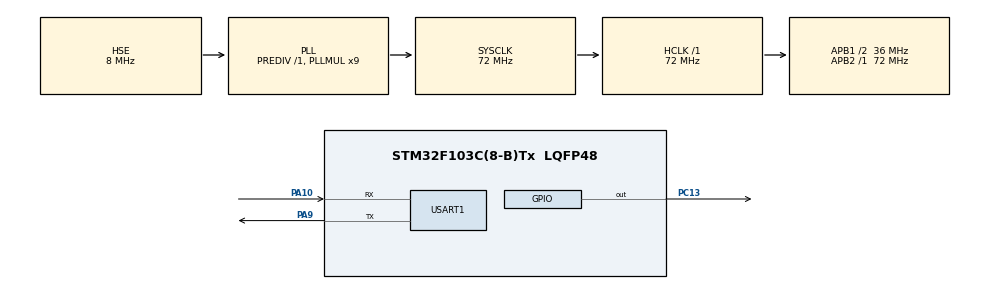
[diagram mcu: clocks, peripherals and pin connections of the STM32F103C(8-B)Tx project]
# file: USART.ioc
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Mcu.Family=STM32F1
Mcu.Name=STM32F103C(8-B)Tx
Mcu.Package=LQFP48
NVIC.PriorityGroup=NVIC_PRIORITYGROUP_4
NVIC.USART1_IRQn=true\:0\:0\:false\:false\:true\:true\:true\:true
PA10.Mode=Asynchronous
PA10.Signal=USART1_RX
PA13.Mode=Serial_Wire
PA13.Signal=SYS_JTMS-SWDIO
PA14.Mode=Serial_Wire
PA14.Signal=SYS_JTCK-SWCLK
PA9.Mode=Asynchronous
PA9.Signal=USART1_TX
PC13-TAMPER-RTC.Signal=GPIO_Output
PD0-OSC_IN.Mode=HSE-External-Oscillator
PD0-OSC_IN.Signal=RCC_OSC_IN
PD1-OSC_OUT.Mode=HSE-External-Oscillator
PD1-OSC_OUT.Signal=RCC_OSC_OUT
ProjectManager.HeapSize=0x200
ProjectManager.StackSize=0x400
ProjectManager.TargetToolchain=MDK-ARM V5.32
RCC.AHBFreq_Value=72000000
RCC.APB1CLKDivider=RCC_HCLK_DIV2
RCC.APB1Freq_Value=36000000
RCC.APB1TimFreq_Value=72000000
RCC.APB2Freq_Value=72000000
RCC.APB2TimFreq_Value=72000000
RCC.HCLKFreq_Value=72000000
RCC.PLLMUL=RCC_PLL_MUL9
RCC.PLLSourceVirtual=RCC_PLLSOURCE_HSE
RCC.SYSCLKFreq_VALUE=72000000
RCC.SYSCLKSource=RCC_SYSCLKSOURCE_PLLCLK
RCC.USBFreq_Value=72000000
USART1.VirtualMode=VM_ASYNC
board=custom

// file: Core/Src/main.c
/* USER CODE BEGIN Header */
/**
  ******************************************************************************
  * @file           : main.c
  * @brief          : Main program body
  ******************************************************************************
  * @attention
  *
  * Copyright (c) 2026 STMicroelectronics.
  * All rights reserved.
  *
  * This software is licensed under terms that can be found in the LICENSE file
  * in the root directory of this software component.
  * If no LICENSE file comes with this software, it is provided AS-IS.
  *
  ******************************************************************************
  */
/* USER CODE END Header */
#include "main.h"

UART_HandleTypeDef huart1;

/* rx_buffer and i are declared once, globally, further down (USER CODE BEGIN 4)
 * so that both main() and HAL_UART_RxCpltCallback() share the SAME variables
 * instead of main() writing to a local shadow copy. Declared volatile since
 * they are shared between interrupt context (the callback) and main(). */
/* USER CODE END PV */
void SystemClock_Config(void);
static void MX_GPIO_Init(void);
static void MX_USART1_UART_Init(void);

int main(void)
{

  /* MCU Configuration--------------------------------------------------------*/

  /* Reset of all peripherals, Initializes the Flash interface and the Systick. */
  HAL_Init();

  /* Configure the system clock */
  SystemClock_Config();

  /* Initialize all configured peripherals */
  MX_GPIO_Init();
  MX_USART1_UART_Init();
  /* USER CODE BEGIN 2 */
uint8_t DATA[] = "TEST \r \n";
uint8_t rx_buffer[12] = {0};
uint8_t i =0;
uint8_t data2[]={1,2,3,4};
  /* USER CODE END 2 */

  /* Infinite loop */
  /* USER CODE BEGIN WHILE */
  while (1)
  {

// TANSSMIT DATA WITH serial communication

		// Block until up to 12 bytes are received, or 5s timeout elapses.
		// rx_buffer will hold whatever bytes arrived (fewer than 12 if the
		// sender stops early, e.g. after pressing Enter in a terminal).
		HAL_UART_Receive (&huart1,rx_buffer, 12,5000);

		// Scan rx_buffer for a carriage return (ASCII 13, '\r'), which marks
		// the end of the line the user typed. i ends up pointing at the
		// index of that '\r'.
		// NOTE: if no '\r' is ever received (e.g. timeout with garbage or
		// no data), this loop reads past the buffer with no bound check —
		// fine for this quick training test, but not safe for production code.
		while(rx_buffer[i] != 13)i++;

		// Echo back only the bytes received before the '\r' (i.e. the
		// actual line content, not the '\r' itself or trailing buffer junk).
    HAL_UART_Transmit(&huart1,rx_buffer, i, 100);
		HAL_Delay(500);

/////////////////////// INCREMENTING COUNTER TEST (interrupt transmit) //////
		// Send only the first byte of data2 using interrupt-driven transmit.
		// HAL_UART_Transmit_IT() returns immediately; the actual transfer
		// happens in the background via USART1 interrupt.
    HAL_UART_Transmit_IT(&huart1,data2,1);

		// Give the interrupt transmit time to finish, and make each byte
		// visible on the receiving terminal at a readable pace.
		HAL_Delay(500);

		// Overwrite data2[0] with the current value of counter i, then
		// increment i for next time. Each loop iteration transmits the next
		// value in the sequence: 0, 1, 2, 3... This tests that repeated
		// interrupt-driven transmits work correctly back-to-back.
		data2[0]=i++;
///////////////////////////////////////////
    /* USER CODE END WHILE */

  }
}

void SystemClock_Config(void)
{
  RCC_OscInitTypeDef RCC_OscInitStruct = {0};
  RCC_ClkInitTypeDef RCC_ClkInitStruct = {0};

  /** Initializes the RCC Oscillators according to the specified parameters
  * in the RCC_OscInitTypeDef structure.
  */
  RCC_OscInitStruct.OscillatorType = RCC_OSCILLATORTYPE_HSE;
  RCC_OscInitStruct.HSEState = RCC_HSE_ON;
  RCC_OscInitStruct.HSEPredivValue = RCC_HSE_PREDIV_DIV1;
  RCC_OscInitStruct.HSIState = RCC_HSI_ON;
  RCC_OscInitStruct.PLL.PLLState = RCC_PLL_ON;
  RCC_OscInitStruct.PLL.PLLSource = RCC_PLLSOURCE_HSE;
  RCC_OscInitStruct.PLL.PLLMUL = RCC_PLL_MUL9;
  if (HAL_RCC_OscConfig(&RCC_OscInitStruct) != HAL_OK)
  {
    Error_Handler();
  }

  /** Initializes the CPU, AHB and APB buses clocks
  */
  RCC_ClkInitStruct.ClockType = RCC_CLOCKTYPE_HCLK|RCC_CLOCKTYPE_SYSCLK
                              |RCC_CLOCKTYPE_PCLK1|RCC_CLOCKTYPE_PCLK2;
  RCC_ClkInitStruct.SYSCLKSource = RCC_SYSCLKSOURCE_PLLCLK;
  RCC_ClkInitStruct.AHBCLKDivider = RCC_SYSCLK_DIV1;
  RCC_ClkInitStruct.APB1CLKDivider = RCC_HCLK_DIV2;
  RCC_ClkInitStruct.APB2CLKDivider = RCC_HCLK_DIV1;

  if (HAL_RCC_ClockConfig(&RCC_ClkInitStruct, FLASH_LATENCY_2) != HAL_OK)
  {
    Error_Handler();
  }
}

static void MX_USART1_UART_Init(void)
{

  huart1.Instance = USART1;
  huart1.Init.BaudRate = 115200;
  huart1.Init.WordLength = UART_WORDLENGTH_8B;
  huart1.Init.StopBits = UART_STOPBITS_1;
  huart1.Init.Parity = UART_PARITY_NONE;
  huart1.Init.Mode = UART_MODE_TX_RX;
  huart1.Init.HwFlowCtl = UART_HWCONTROL_NONE;
  huart1.Init.OverSampling = UART_OVERSAMPLING_16;
  if (HAL_UART_Init(&huart1) != HAL_OK)
  {
    Error_Handler();
  }

}

static void MX_GPIO_Init(void)
{
  GPIO_InitTypeDef GPIO_InitStruct = {0};

  /* GPIO Ports Clock Enable */
  __HAL_RCC_GPIOC_CLK_ENABLE();
  __HAL_RCC_GPIOD_CLK_ENABLE();
  __HAL_RCC_GPIOA_CLK_ENABLE();

  /*Configure GPIO pin Output Level */
  HAL_GPIO_WritePin(GPIOC, GPIO_PIN_13, GPIO_PIN_RESET);

  /*Configure GPIO pin : PC13 */
  GPIO_InitStruct.Pin = GPIO_PIN_13;
  GPIO_InitStruct.Mode = GPIO_MODE_OUTPUT_PP;
  GPIO_InitStruct.Pull = GPIO_NOPULL;
  GPIO_InitStruct.Speed = GPIO_SPEED_FREQ_LOW;
  HAL_GPIO_Init(GPIOC, &GPIO_InitStruct);

}

/* USER CODE BEGIN 4 */
uint8_t rx_buffer[12] = {0};
uint8_t i =0;
void HAL_UART_RxCpltCallback(UART_HandleTypeDef *huart)
{if( huart->Instance == USART1){
HAL_GPIO_TogglePin(GPIOC,GPIO_PIN_13);
}
}
/* USER CODE END 4 */

void Error_Handler(void)
{
  __disable_irq();
  while (1)
  {
  }
}
